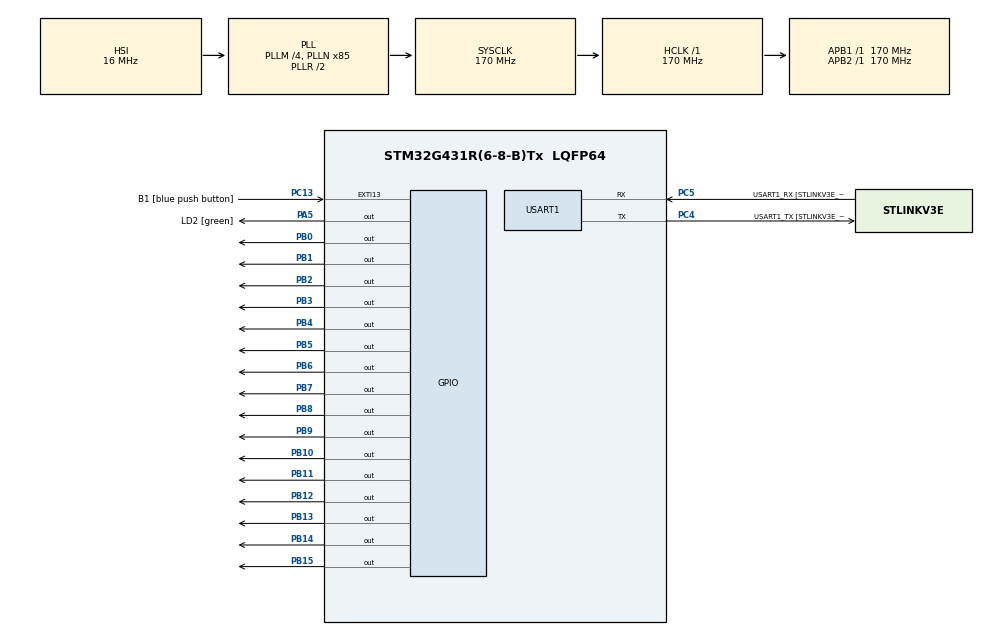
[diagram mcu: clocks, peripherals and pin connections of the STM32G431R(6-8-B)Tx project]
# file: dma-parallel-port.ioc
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Dma.Request0=TIM6_UP
Dma.TIM6_UP.0.Direction=DMA_MEMORY_TO_PERIPH
Dma.TIM6_UP.0.EventEnable=DISABLE
Dma.TIM6_UP.0.Instance=DMA1_Channel1
Dma.TIM6_UP.0.MemDataAlignment=DMA_MDATAALIGN_HALFWORD
Dma.TIM6_UP.0.MemInc=DMA_MINC_ENABLE
Dma.TIM6_UP.0.Mode=DMA_CIRCULAR
Dma.TIM6_UP.0.PeriphDataAlignment=DMA_PDATAALIGN_HALFWORD
Dma.TIM6_UP.0.PeriphInc=DMA_PINC_DISABLE
Dma.TIM6_UP.0.Polarity=HAL_DMAMUX_REQ_GEN_RISING
Dma.TIM6_UP.0.Priority=DMA_PRIORITY_LOW
Dma.TIM6_UP.0.RequestNumber=1
Dma.TIM6_UP.0.SignalID=NONE
Dma.TIM6_UP.0.SyncEnable=DISABLE
Dma.TIM6_UP.0.SyncPolarity=HAL_DMAMUX_SYNC_NO_EVENT
Dma.TIM6_UP.0.SyncRequestNumber=1
Dma.TIM6_UP.0.SyncSignalID=NONE
Mcu.Family=STM32G4
Mcu.Name=STM32G431R(6-8-B)Tx
Mcu.Package=LQFP64
NVIC.DMA1_Channel1_IRQn=true\:0\:0\:false\:false\:true\:false\:true
NVIC.PriorityGroup=NVIC_PRIORITYGROUP_4
PA13.GPIO_Label=T_SWDIO
PA13.Mode=Serial_Wire
PA13.Signal=SYS_JTMS-SWDIO
PA14.GPIO_Label=T_SWCLK
PA14.Mode=Serial_Wire
PA14.Signal=SYS_JTCK-SWCLK
PA5.GPIO_Label=LD2 [green]
PA5.Signal=GPIO_Output
PB0.Signal=GPIO_Output
PB1.Signal=GPIO_Output
PB10.Signal=GPIO_Output
PB11.Signal=GPIO_Output
PB12.Signal=GPIO_Output
PB13.Signal=GPIO_Output
PB14.Signal=GPIO_Output
PB15.Signal=GPIO_Output
PB2.Signal=GPIO_Output
PB3.Signal=GPIO_Output
PB4.Signal=GPIO_Output
PB5.Signal=GPIO_Output
PB6.Signal=GPIO_Output
PB7.Signal=GPIO_Output
PB8-BOOT0.Signal=GPIO_Output
PB9.Signal=GPIO_Output
PC13.GPIO_Label=B1 [blue push button]
PC13.Signal=GPXTI13
PC14-OSC32_IN.Mode=LSE-External-Oscillator
PC14-OSC32_IN.Signal=RCC_OSC32_IN
PC15-OSC32_OUT.Mode=LSE-External-Oscillator
PC15-OSC32_OUT.Signal=RCC_OSC32_OUT
PC4.GPIO_Label=USART1_TX [STLINKV3E_VCP_RX]
PC4.Mode=Asynchronous
PC4.Signal=USART1_TX
PC5.GPIO_Label=USART1_RX [STLINKV3E_VCP_TX]
PC5.Mode=Asynchronous
PC5.Signal=USART1_RX
PF0-OSC_IN.Mode=HSE-External-Oscillator
PF0-OSC_IN.Signal=RCC_OSC_IN
PF1-OSC_OUT.Mode=HSE-External-Oscillator
PF1-OSC_OUT.Signal=RCC_OSC_OUT
ProjectManager.HeapSize=0x200
ProjectManager.StackSize=0x400
ProjectManager.TargetToolchain=STM32CubeIDE
RCC.ADC12Freq_Value=170000000
RCC.AHBFreq_Value=170000000
RCC.APB1Freq_Value=170000000
RCC.APB1TimFreq_Value=170000000
RCC.APB2Freq_Value=170000000
RCC.APB2TimFreq_Value=170000000
RCC.CortexFreq_Value=170000000
RCC.EXTERNAL_CLOCK_VALUE=12288000
RCC.HCLKFreq_Value=170000000
RCC.HSE_VALUE=24000000
RCC.HSI48_VALUE=48000000
RCC.HSI_VALUE=16000000
RCC.PLLM=RCC_PLLM_DIV4
RCC.PLLN=85
RCC.RTCClockSelection=RCC_RTCCLKSOURCE_LSE
RCC.SYSCLKFreq_VALUE=170000000
RCC.SYSCLKSource=RCC_SYSCLKSOURCE_PLLCLK
RCC.USBFreq_Value=170000000
RCC.VCOOutputFreq_Value=340000000
TIM6.AutoReloadPreload=TIM_AUTORELOAD_PRELOAD_ENABLE
TIM6.PeriodNoDither=399
TIM6.Prescaler=299
USART1.VirtualMode-Asynchronous=VM_ASYNC
USART1.WordLength=WORDLENGTH_8B
VP_SYS_VS_DBSignals.Mode=DisableDeadBatterySignals
VP_TIM6_VS_ClockSourceINT.Mode=Enable_Timer
board=NUCLEO-G431RB

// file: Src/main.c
/* USER CODE BEGIN Header */
/**
  ******************************************************************************
  * @file           : main.c
  * @brief          : Main program body
  ******************************************************************************
  * @attention
  *
  * <h2><center>&copy; Copyright (c) 2019 STMicroelectronics.
  * All rights reserved.</center></h2>
  *
  * This software component is licensed by ST under BSD 3-Clause license,
  * the "License"; You may not use this file except in compliance with the
  * License. You may obtain a copy of the License at:
  *                        opensource.org/licenses/BSD-3-Clause
  *
  ******************************************************************************
  */
/* USER CODE END Header */

#include "main.h"
#include "dma.h"
#include "tim.h"
#include "usart.h"
#include "gpio.h"

void SystemClock_Config(void);
/* USER CODE BEGIN PFP */

void app_main();
/* USER CODE END PFP */

int main(void)
{

  /* MCU Configuration--------------------------------------------------------*/

  /* Reset of all peripherals, Initializes the Flash interface and the Systick. */
  HAL_Init();

  /* Configure the system clock */
  SystemClock_Config();

  /* USER CODE BEGIN SysInit */
  app_main();
  // The rest of this file is unused
  /* USER CODE END SysInit */

  /* Initialize all configured peripherals */
  MX_GPIO_Init();
  MX_DMA_Init();
  MX_TIM6_Init();
  MX_USART1_UART_Init();

  /* Infinite loop */
  while (1)
  {

  }
}

void SystemClock_Config(void)
{
  RCC_OscInitTypeDef RCC_OscInitStruct = {0};
  RCC_ClkInitTypeDef RCC_ClkInitStruct = {0};
  RCC_PeriphCLKInitTypeDef PeriphClkInit = {0};

  /** Configure the main internal regulator output voltage
  */
  HAL_PWREx_ControlVoltageScaling(PWR_REGULATOR_VOLTAGE_SCALE1_BOOST);
  /** Initializes the CPU, AHB and APB busses clocks
  */
  RCC_OscInitStruct.OscillatorType = RCC_OSCILLATORTYPE_HSI;
  RCC_OscInitStruct.HSIState = RCC_HSI_ON;
  RCC_OscInitStruct.HSICalibrationValue = RCC_HSICALIBRATION_DEFAULT;
  RCC_OscInitStruct.PLL.PLLState = RCC_PLL_ON;
  RCC_OscInitStruct.PLL.PLLSource = RCC_PLLSOURCE_HSI;
  RCC_OscInitStruct.PLL.PLLM = RCC_PLLM_DIV4;
  RCC_OscInitStruct.PLL.PLLN = 85;
  RCC_OscInitStruct.PLL.PLLP = RCC_PLLP_DIV2;
  RCC_OscInitStruct.PLL.PLLQ = RCC_PLLQ_DIV2;
  RCC_OscInitStruct.PLL.PLLR = RCC_PLLR_DIV2;
  if (HAL_RCC_OscConfig(&RCC_OscInitStruct) != HAL_OK)
  {
    Error_Handler();
  }
  /** Initializes the CPU, AHB and APB busses clocks
  */
  RCC_ClkInitStruct.ClockType = RCC_CLOCKTYPE_HCLK|RCC_CLOCKTYPE_SYSCLK
                              |RCC_CLOCKTYPE_PCLK1|RCC_CLOCKTYPE_PCLK2;
  RCC_ClkInitStruct.SYSCLKSource = RCC_SYSCLKSOURCE_PLLCLK;
  RCC_ClkInitStruct.AHBCLKDivider = RCC_SYSCLK_DIV1;
  RCC_ClkInitStruct.APB1CLKDivider = RCC_HCLK_DIV1;
  RCC_ClkInitStruct.APB2CLKDivider = RCC_HCLK_DIV1;

  if (HAL_RCC_ClockConfig(&RCC_ClkInitStruct, FLASH_LATENCY_8) != HAL_OK)
  {
    Error_Handler();
  }
  /** Initializes the peripherals clocks
  */
  PeriphClkInit.PeriphClockSelection = RCC_PERIPHCLK_USART1;
  PeriphClkInit.Usart1ClockSelection = RCC_USART1CLKSOURCE_PCLK2;
  if (HAL_RCCEx_PeriphCLKConfig(&PeriphClkInit) != HAL_OK)
  {
    Error_Handler();
  }
}

void Error_Handler(void)
{
}

/************************ (C) COPYRIGHT STMicroelectronics *****END OF FILE****/
